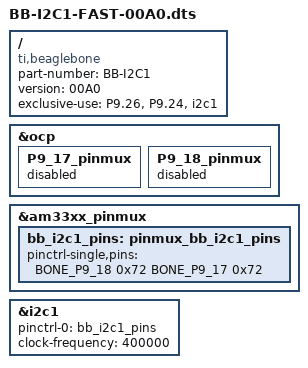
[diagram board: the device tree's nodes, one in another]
/*
 * Copyright (C) 2013 CircuitCo
 *
 * Virtual cape for I2C1 on connector pins P9.17 P9.18
 *
 * This program is free software; you can redistribute it and/or modify
 * it under the terms of the GNU General Public License version 2 as
 * published by the Free Software Foundation.
 */

/dts-v1/;
/plugin/;

#include <dt-bindings/board/am335x-bbw-bbb-base.h>
#include <dt-bindings/pinctrl/am33xx.h>

/ {
	compatible = "ti,beaglebone", "ti,beaglebone-black", "ti,beaglebone-green";

	// identification
	part-number = "BB-I2C1";
	version = "00A0";

	// resources this cape uses
	exclusive-use =
		"P9.26",	// i2c1_sda
		"P9.24",	// i2c1_scl

		"i2c1";		// hardware ip used

	/*
	 * Free up the pins used by the cape from the pinmux helpers.
	 */
	fragment@0 {
		target = <&ocp>;
		__overlay__ {
			P9_17_pinmux { status = "disabled"; };	/* i2c1_scl */
			P9_18_pinmux { status = "disabled"; };	/* i2c1_sda */
		};
	};

	fragment@1 {
		target = <&am33xx_pinmux>;
		__overlay__ {
			bb_i2c1_pins: pinmux_bb_i2c1_pins {
				pinctrl-single,pins = <
					BONE_P9_18 0x72	/* spi0_d1.i2c1_sda, SLEWCTRL_SLOW | INPUT_PULLUP | MODE2 */
					BONE_P9_17 0x72	/* spi0_cs0.i2c1_scl, SLEWCTRL_SLOW | INPUT_PULLUP | MODE2 */
				>;
			};
		};
	};

	fragment@2 {
		target = <&i2c1>;
		__overlay__ {
			status = "okay";
			pinctrl-names = "default";
			pinctrl-0 = <&bb_i2c1_pins>;

			/* this is the configuration part */
			clock-frequency = <400000>;

			#address-cells = <1>;
			#size-cells = <0>;

			/* add any i2c devices on the bus here */

			// commented out example of a touchscreen (taken from BB-BONE-LCD7-01-00A4) */
			// maxtouch@4a {
			//	compatible = "mXT224";
			//	reg = <0x4a>;
			//	interrupt-parent = <&gpio4>;
			//	interrupts = <19 0x0>;
			//	atmel,irq-gpio = <&gpio4 19 0>;
			// };
		};
	};
};
